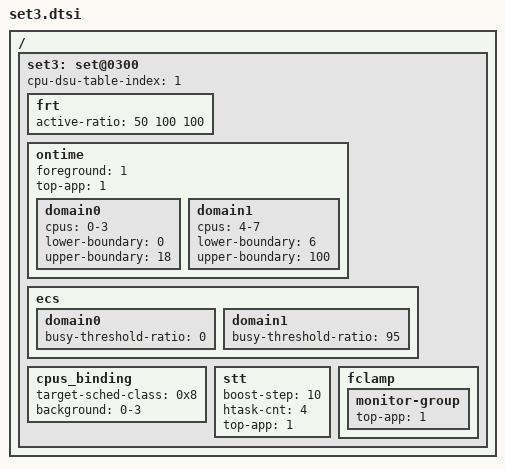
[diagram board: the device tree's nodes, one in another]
/ {
	/* game mode - default */
	set3: set@0300{
		cpu-dsu-table-index = <1>;

		frt {	   			/* LIT MED BIG */
			active-ratio 		= < 50 100 100>;
		};

		/* Ontime Migration */
		ontime {
			foreground	= <1>;
			top-app		= <1>;

			domain0 {
				cpus = "0-3";
				lower-boundary = <0>;
				upper-boundary = <18>;
			};
			domain1 {
				cpus = "4-7";
				lower-boundary = <6>;
				upper-boundary = <100>;
			};
		};

		ecs {
			domain0 {
				busy-threshold-ratio = <0>;
			};
			domain1 {
				busy-threshold-ratio = <95>;
			};
		};

		/* cpus_binding applied to core selection */
		cpus_binding {
			target-sched-class = <0x8>;	/* fair */

			background	= "0-3";
		};

		stt {
			boost-step		= <10>;
			htask-cnt		= <4>;
			top-app			= <1>;
		};

		fclamp {
			monitor-group {
				top-app         = <1>;
			};
		};
	};
};
